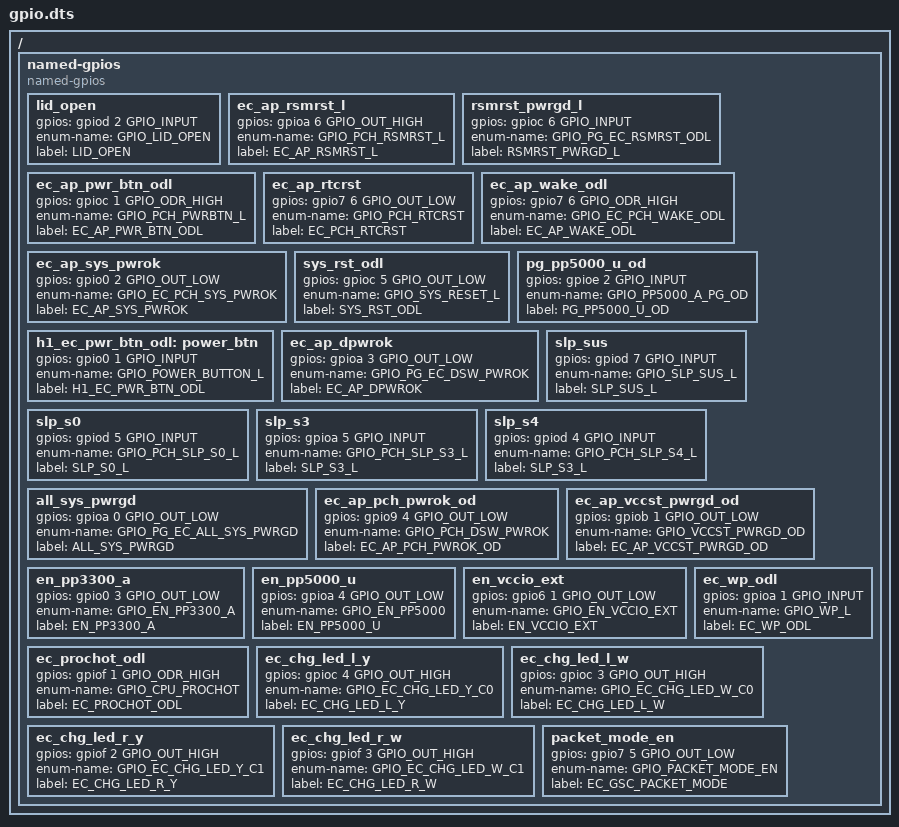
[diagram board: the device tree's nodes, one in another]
/* Copyright 2021 The Chromium OS Authors. All rights reserved.
 * Use of this source code is governed by a BSD-style license that can be
 * found in the LICENSE file.
 */

/ {
	named-gpios {
		compatible = "named-gpios";

		lid_open: lid_open {
			gpios = <&gpiod 2 GPIO_INPUT>;
			enum-name = "GPIO_LID_OPEN";
			label = "LID_OPEN";
		};
		ec_ap_rsmrst_l {
			gpios = <&gpioa 6 GPIO_OUT_HIGH>;
			enum-name = "GPIO_PCH_RSMRST_L";
			label = "EC_AP_RSMRST_L";
		};
		rsmrst_pwrgd_l {
			gpios = <&gpioc 6 GPIO_INPUT>;
			enum-name = "GPIO_PG_EC_RSMRST_ODL";
			label = "RSMRST_PWRGD_L";
		};
		ec_ap_pwr_btn_odl {
			gpios = <&gpioc 1 GPIO_ODR_HIGH>;
			enum-name = "GPIO_PCH_PWRBTN_L";
			label = "EC_AP_PWR_BTN_ODL";
		};
		ec_ap_rtcrst {
			gpios = <&gpio7 6 GPIO_OUT_LOW>;
			enum-name = "GPIO_PCH_RTCRST";
			label = "EC_PCH_RTCRST";
		};
		ec_ap_wake_odl {
			gpios = <&gpio7 6 GPIO_ODR_HIGH>;
			enum-name = "GPIO_EC_PCH_WAKE_ODL";
			label = "EC_AP_WAKE_ODL";
		};
		ec_ap_sys_pwrok {
			gpios = <&gpio0 2 GPIO_OUT_LOW>;
			enum-name = "GPIO_EC_PCH_SYS_PWROK";
			label = "EC_AP_SYS_PWROK";
		};
		sys_rst_odl {
			gpios = <&gpioc 5 GPIO_OUT_LOW>;
			enum-name = "GPIO_SYS_RESET_L";
			label = "SYS_RST_ODL";
		};
		pg_pp5000_u_od {
			gpios = <&gpioe 2 GPIO_INPUT>;
			enum-name = "GPIO_PP5000_A_PG_OD";
			label = "PG_PP5000_U_OD";
		};
		h1_ec_pwr_btn_odl: power_btn {
			gpios = <&gpio0 1 GPIO_INPUT>;
			enum-name = "GPIO_POWER_BUTTON_L";
			label = "H1_EC_PWR_BTN_ODL";
		};
		ec_ap_dpwrok {
			gpios = <&gpioa 3 GPIO_OUT_LOW>;
			enum-name = "GPIO_PG_EC_DSW_PWROK";
			label = "EC_AP_DPWROK";
		};
		slp_sus {
			gpios = <&gpiod 7 GPIO_INPUT>;
			enum-name = "GPIO_SLP_SUS_L";
			label = "SLP_SUS_L";
		};
		slp_s0 {
			gpios = <&gpiod 5 GPIO_INPUT>;
			enum-name = "GPIO_PCH_SLP_S0_L";
			label = "SLP_S0_L";
		};
		slp_s3 {
			gpios = <&gpioa 5 GPIO_INPUT>;
			enum-name = "GPIO_PCH_SLP_S3_L";
			label = "SLP_S3_L";
		};
		slp_s4 {
			gpios = <&gpiod 4 GPIO_INPUT>;
			enum-name = "GPIO_PCH_SLP_S4_L";
			label = "SLP_S3_L";
		};
		all_sys_pwrgd {
			gpios = <&gpioa 0 GPIO_OUT_LOW>;
			enum-name = "GPIO_PG_EC_ALL_SYS_PWRGD";
			label = "ALL_SYS_PWRGD";
		};
		ec_ap_pch_pwrok_od {
			gpios = <&gpio9 4 GPIO_OUT_LOW>;
			enum-name = "GPIO_PCH_DSW_PWROK";
			label = "EC_AP_PCH_PWROK_OD";
		};
		ec_ap_vccst_pwrgd_od {
			gpios = <&gpiob 1 GPIO_OUT_LOW>;
			enum-name = "GPIO_VCCST_PWRGD_OD";
			label = "EC_AP_VCCST_PWRGD_OD";
		};
		en_pp3300_a {
			gpios = <&gpio0 3 GPIO_OUT_LOW>;
			enum-name = "GPIO_EN_PP3300_A";
			label = "EN_PP3300_A";
		};
		en_pp5000_u {
			gpios = <&gpioa 4 GPIO_OUT_LOW>;
			enum-name = "GPIO_EN_PP5000";
			label = "EN_PP5000_U";
		};
		en_vccio_ext {
			gpios = <&gpio6 1 GPIO_OUT_LOW>;
			enum-name = "GPIO_EN_VCCIO_EXT";
			label = "EN_VCCIO_EXT";
		};
		ec_prochot_odl {
			gpios = <&gpiof 1 GPIO_ODR_HIGH>;
			enum-name = "GPIO_CPU_PROCHOT";
			label = "EC_PROCHOT_ODL";
		};
		ec_wp_odl {
			gpios = <&gpioa 1 GPIO_INPUT>;
			enum-name = "GPIO_WP_L";
			label = "EC_WP_ODL";
		};
		ec_chg_led_l_y {
			gpios = <&gpioc 4 GPIO_OUT_HIGH>;
			enum-name = "GPIO_EC_CHG_LED_Y_C0";
			label = "EC_CHG_LED_L_Y";
		};
		ec_chg_led_l_w {
			gpios = <&gpioc 3 GPIO_OUT_HIGH>;
			enum-name = "GPIO_EC_CHG_LED_W_C0";
			label = "EC_CHG_LED_L_W";
		};
		ec_chg_led_r_y {
			gpios = <&gpiof 2 GPIO_OUT_HIGH>;
			enum-name = "GPIO_EC_CHG_LED_Y_C1";
			label = "EC_CHG_LED_R_Y";
		};
		ec_chg_led_r_w {
			gpios = <&gpiof 3 GPIO_OUT_HIGH>;
			enum-name = "GPIO_EC_CHG_LED_W_C1";
			label = "EC_CHG_LED_R_W";
		};
		packet_mode_en {
			gpios = <&gpio7 5 GPIO_OUT_LOW>;
			enum-name = "GPIO_PACKET_MODE_EN";
			label = "EC_GSC_PACKET_MODE";
		};
	};
};
